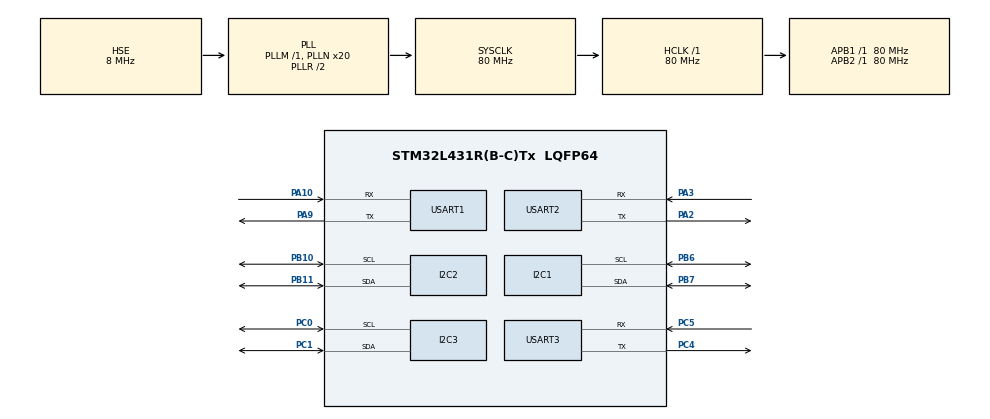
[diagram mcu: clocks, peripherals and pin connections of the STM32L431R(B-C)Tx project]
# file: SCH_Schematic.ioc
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FREERTOS.Tasks01=defaultTask,24,128,StartDefaultTask,Default,NULL,Dynamic,NULL,NULL
FREERTOS.configTOTAL_HEAP_SIZE=15360
FREERTOS.configUSE_TRACE_FACILITY=1
I2C1.Timing=0x10909CEC
I2C2.Timing=0x10909CEC
I2C3.Timing=0x10909CEC
Mcu.Family=STM32L4
Mcu.Name=STM32L431R(B-C)Tx
Mcu.Package=LQFP64
NVIC.PriorityGroup=NVIC_PRIORITYGROUP_4
NVIC.TIM1_UP_TIM16_IRQn=true\:15\:0\:false\:false\:true\:false\:false\:true\:true
NVIC.TimeBase=TIM1_UP_TIM16_IRQn
NVIC.TimeBaseIP=TIM1
NVIC.USART1_IRQn=true\:5\:0\:false\:false\:true\:true\:true\:true\:true
NVIC.USART2_IRQn=true\:5\:0\:false\:false\:true\:true\:true\:true\:true
NVIC.USART3_IRQn=true\:5\:0\:false\:false\:true\:true\:true\:true\:true
PA10.Mode=Asynchronous
PA10.Signal=USART1_RX
PA13\ (JTMS-SWDIO).Mode=JTAG_5_pins
PA13\ (JTMS-SWDIO).Signal=SYS_JTMS-SWDIO
PA14\ (JTCK-SWCLK).Mode=JTAG_5_pins
PA14\ (JTCK-SWCLK).Signal=SYS_JTCK-SWCLK
PA15\ (JTDI).Mode=JTAG_5_pins
PA15\ (JTDI).Signal=SYS_JTDI
PA2.Mode=Asynchronous
PA2.Signal=USART2_TX
PA3.Mode=Asynchronous
PA3.Signal=USART2_RX
PA9.Mode=Asynchronous
PA9.Signal=USART1_TX
PB10.Mode=I2C
PB10.Signal=I2C2_SCL
PB11.Mode=I2C
PB11.Signal=I2C2_SDA
PB3\ (JTDO-TRACESWO).Mode=JTAG_5_pins
PB3\ (JTDO-TRACESWO).Signal=SYS_JTDO-SWO
PB4\ (NJTRST).Mode=JTAG_5_pins
PB4\ (NJTRST).Signal=SYS_JTRST
PB6.Mode=I2C
PB6.Signal=I2C1_SCL
PB7.Mode=I2C
PB7.Signal=I2C1_SDA
PC0.Mode=I2C
PC0.Signal=I2C3_SCL
PC1.Mode=I2C
PC1.Signal=I2C3_SDA
PC14-OSC32_IN\ (PC14).Mode=LSE-External-Oscillator
PC14-OSC32_IN\ (PC14).Signal=RCC_OSC32_IN
PC15-OSC32_OUT\ (PC15).Mode=LSE-External-Oscillator
PC15-OSC32_OUT\ (PC15).Signal=RCC_OSC32_OUT
PC4.Mode=Asynchronous
PC4.Signal=USART3_TX
PC5.Mode=Asynchronous
PC5.Signal=USART3_RX
PH0-OSC_IN\ (PH0).Mode=HSE-External-Oscillator
PH0-OSC_IN\ (PH0).Signal=RCC_OSC_IN
PH1-OSC_OUT\ (PH1).Mode=HSE-External-Oscillator
PH1-OSC_OUT\ (PH1).Signal=RCC_OSC_OUT
ProjectManager.HeapSize=0x2000
ProjectManager.StackSize=0x4000
ProjectManager.TargetToolchain=MDK-ARM V5.32
RCC.ADCFreq_Value=32000000
RCC.AHBFreq_Value=80000000
RCC.APB1Freq_Value=80000000
RCC.APB1TimFreq_Value=80000000
RCC.APB2Freq_Value=80000000
RCC.APB2TimFreq_Value=80000000
RCC.CortexFreq_Value=80000000
RCC.HCLKFreq_Value=80000000
RCC.HSE_VALUE=8000000
RCC.HSI48_VALUE=48000000
RCC.HSI_VALUE=16000000
RCC.LSE_Drive_CapabilityArg=+LSE_Drive_Capability
RCC.MSIAutoCalibration=DISABLED
RCC.MSI_VALUE=4000000
RCC.PLLN=20
RCC.PLLSourceVirtual=RCC_PLLSOURCE_HSE
RCC.SYSCLKFreq_VALUE=80000000
RCC.SYSCLKSource=RCC_SYSCLKSOURCE_PLLCLK
RCC.VCOOutputFreq_Value=160000000
USART1.VirtualMode-Asynchronous=VM_ASYNC
USART2.VirtualMode-Asynchronous=VM_ASYNC
USART3.VirtualMode-Asynchronous=VM_ASYNC
VP_FREERTOS_VS_CMSIS_V2.Mode=CMSIS_V2
VP_IWDG_VS_IWDG.Mode=IWDG_Activate
VP_SYS_VS_tim1.Mode=TIM1
board=custom

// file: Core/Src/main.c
/* USER CODE BEGIN Header */
/**
  ******************************************************************************
  * @file           : main.c
  * @brief          : Main program body
  ******************************************************************************
  * @attention
  *
  * Copyright (c) 2025 STMicroelectronics.
  * All rights reserved.
  *
  * This software is licensed under terms that can be found in the LICENSE file
  * in the root directory of this software component.
  * If no LICENSE file comes with this software, it is provided AS-IS.
  *
  ******************************************************************************
  */
/* USER CODE END Header */
#include "main.h"
#include "cmsis_os.h"
#include "i2c.h"
#include "iwdg.h"
#include "usart.h"
#include "gpio.h"

void SystemClock_Config(void);
void MX_FREERTOS_Init(void);

int main(void)
{
  /* USER CODE BEGIN 1 */
	uint8_t aa;
  /* USER CODE END 1 */

  /* MCU Configuration--------------------------------------------------------*/

  /* Reset of all peripherals, Initializes the Flash interface and the Systick. */
  HAL_Init();

  /* Configure the system clock */
  SystemClock_Config();

  /* Initialize all configured peripherals */
  MX_GPIO_Init();
  MX_I2C1_Init();
  MX_I2C2_Init();
  MX_I2C3_Init();
  MX_IWDG_Init();
  MX_USART1_UART_Init();
  MX_USART2_UART_Init();
  MX_USART3_UART_Init();
  /* USER CODE BEGIN 2 */
  OLED_Init();
	OLED_Clear();
  /* USER CODE END 2 */

  /* Init scheduler */
  osKernelInitialize();  /* Call init function for freertos objects (in freertos.c) */
  MX_FREERTOS_Init();

  /* Start scheduler */
  osKernelStart();

  /* We should never get here as control is now taken by the scheduler */
  /* Infinite loop */
  while (1)
  {

    /* USER CODE BEGIN 3 */
    OLED_ShowString(8,4,"ASD",16); //表示x=4，y=8开始显示字符串

    aa=123;
    OLED_ShowChar(8,6,48+aa/100,16);     //显示一个字符
    OLED_ShowChar(16,6,48+aa%100/10,16);
    OLED_ShowChar(24,6,48+aa%100%10,16);
  }
  /* USER CODE END 3 */
}

void SystemClock_Config(void)
{
  RCC_OscInitTypeDef RCC_OscInitStruct = {0};
  RCC_ClkInitTypeDef RCC_ClkInitStruct = {0};

  /** Configure the main internal regulator output voltage
  */
  if (HAL_PWREx_ControlVoltageScaling(PWR_REGULATOR_VOLTAGE_SCALE1) != HAL_OK)
  {
    Error_Handler();
  }

  /** Initializes the RCC Oscillators according to the specified parameters
  * in the RCC_OscInitTypeDef structure.
  */
  RCC_OscInitStruct.OscillatorType = RCC_OSCILLATORTYPE_LSI|RCC_OSCILLATORTYPE_HSE;
  RCC_OscInitStruct.HSEState = RCC_HSE_ON;
  RCC_OscInitStruct.LSIState = RCC_LSI_ON;
  RCC_OscInitStruct.PLL.PLLState = RCC_PLL_ON;
  RCC_OscInitStruct.PLL.PLLSource = RCC_PLLSOURCE_HSE;
  RCC_OscInitStruct.PLL.PLLM = 1;
  RCC_OscInitStruct.PLL.PLLN = 20;
  RCC_OscInitStruct.PLL.PLLP = RCC_PLLP_DIV7;
  RCC_OscInitStruct.PLL.PLLQ = RCC_PLLQ_DIV2;
  RCC_OscInitStruct.PLL.PLLR = RCC_PLLR_DIV2;
  if (HAL_RCC_OscConfig(&RCC_OscInitStruct) != HAL_OK)
  {
    Error_Handler();
  }

  /** Initializes the CPU, AHB and APB buses clocks
  */
  RCC_ClkInitStruct.ClockType = RCC_CLOCKTYPE_HCLK|RCC_CLOCKTYPE_SYSCLK
                              |RCC_CLOCKTYPE_PCLK1|RCC_CLOCKTYPE_PCLK2;
  RCC_ClkInitStruct.SYSCLKSource = RCC_SYSCLKSOURCE_PLLCLK;
  RCC_ClkInitStruct.AHBCLKDivider = RCC_SYSCLK_DIV1;
  RCC_ClkInitStruct.APB1CLKDivider = RCC_HCLK_DIV1;
  RCC_ClkInitStruct.APB2CLKDivider = RCC_HCLK_DIV1;

  if (HAL_RCC_ClockConfig(&RCC_ClkInitStruct, FLASH_LATENCY_4) != HAL_OK)
  {
    Error_Handler();
  }
}

void HAL_TIM_PeriodElapsedCallback(TIM_HandleTypeDef *htim)
{
  if (htim->Instance == TIM1) {
    HAL_IncTick();
  }
}

void Error_Handler(void)
{
  __disable_irq();
  while (1)
  {
  }
}
